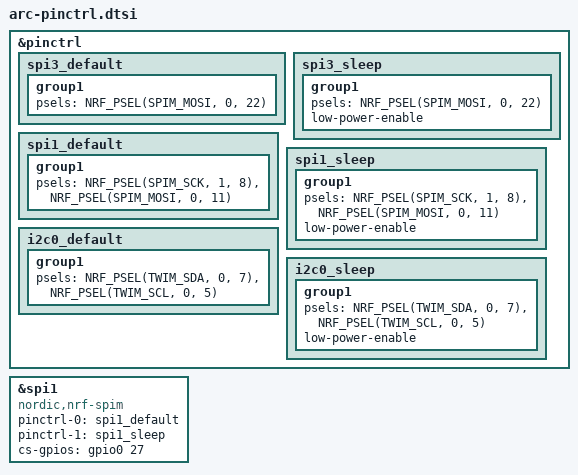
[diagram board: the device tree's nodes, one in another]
#include <dt-bindings/led/led.h>

&pinctrl {
    spi3_default: spi3_default {
        group1 {
            psels = <NRF_PSEL(SPIM_MOSI, 0, 22)>;
        };
    };

    spi3_sleep: spi3_sleep {
        group1 {
            psels = <NRF_PSEL(SPIM_MOSI, 0, 22)>;
            low-power-enable;
        };
    };

    spi1_default: spi1_default {
        group1 {
            psels = <NRF_PSEL(SPIM_SCK, 1, 8)>,
                <NRF_PSEL(SPIM_MOSI, 0, 11)>;
        };
    };

    spi1_sleep: spi1_sleep {
        group1 {
            psels = <NRF_PSEL(SPIM_SCK, 1, 8)>,
                <NRF_PSEL(SPIM_MOSI, 0, 11)>;
            low-power-enable;
        };
    };

    i2c0_default: i2c0_default {
			group1 {
					psels = <NRF_PSEL(TWIM_SDA, 0, 7)>,
						<NRF_PSEL(TWIM_SCL, 0, 5)>;

			};
	};

	i2c0_sleep: i2c0_sleep {
			group1 {
					psels = <NRF_PSEL(TWIM_SDA, 0, 7)>,
						<NRF_PSEL(TWIM_SCL, 0, 5)>;
					low-power-enable;
			};
	};

};

nice_view_spi: &spi1 {
    compatible = "nordic,nrf-spim";
    pinctrl-0 = <&spi1_default>;
    pinctrl-1 = <&spi1_sleep>;
    pinctrl-names = "default", "sleep";
    cs-gpios = <&gpio0 27 GPIO_ACTIVE_HIGH>;
};

